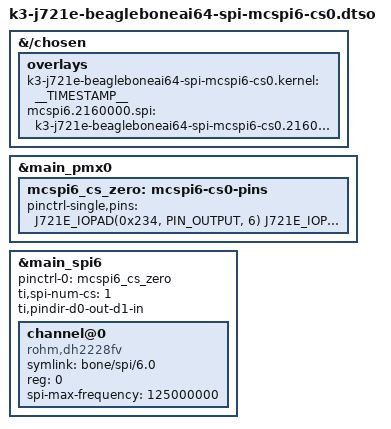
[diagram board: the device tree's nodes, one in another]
// SPDX-License-Identifier: GPL-2.0-only OR MIT
/*
 * DT Overlay for pins P9_28(cs0), P9_31(clk), P9_30(MOSI), P9_29B(MISO) SPI6 connections within the expansion header.
 *
 * Copyright (C) 2023 Texas Instruments Incorporated - https://www.ti.com/
 *
 */

/dts-v1/;
/plugin/;

#include <dt-bindings/gpio/gpio.h>
#include "ti/k3-pinctrl.h"

/*
 * Helper to show loaded overlays under: /proc/device-tree/chosen/overlays/
*/
&{/chosen} {
        overlays {
                k3-j721e-beagleboneai64-spi-mcspi6-cs0.kernel = __TIMESTAMP__;
                mcspi6.2160000.spi = "k3-j721e-beagleboneai64-spi-mcspi6-cs0.2160000";
        };
};

/* To figure out which SoC pad numbers go with which BB header pins, look at columns A and B
 * in the following spreadsheet. To figure out mux modes, look at row 10.
 * https://drive.google.com/file/d/15NLaUeMBy-iT8s6rFrP4Esf0Qh57T4xu/view?pli=1
 *
 * To figure out the addresses of SoC pads, look at table "Table 5-125. Pin Multiplexing" in the TDA4VM Processors datasheet
 * https://www.ti.com/lit/ds/symlink/tda4vm.pdf?ts=1741890214437&ref_url=https%253A%252F%252Fwww.ti.com%252Fproduct%252FTDA4VM
 *

 * ~~ Walkthrough of process to figure out muxing ~~
 *
 * From the spreadsheet we see that pad AC22 is the first pad on BB header pin P9_22. AC22 is thus known as P9_22a. The alternative
 * pad, U29, is known as P9_22b. From Looking at the TDA4VM datasheet, we see that AC22(aka P9_22a) has the address 0x00011C09C. For 
 * the J721E_IOPAD() pin-mux macro, we need the bottom 24bits of the address, so 0x09c, or 0x9c. 
 * 
 * To mux AC22(aka P9_22a) to be SPI6_CLK, as figured out from the spreadsheet, we need to set AC22 to mux-mode 4. And since
 * a SPI clock is an output signal, the pin should be put set to PIN_OUTPUT mode.
 * So `J721E_IOPAD(0x9c, PIN_OUTPUT, 4)`
 * 
 * We will also need to disable the second SoC pad that shares the same BB header pin. The SoC pad known as pin P9_22b, or 
 * pad U29. Using the same process as walked through with pad AC22, you get the following:
 * `J721E_IOPAD(0x170, PIN_DISABLE, 7)`
 *
 * So to mux SPI6_CLK on BB pin P9_22:
 * J721E_IOPAD(0x9c, PIN_OUTPUT, 4)
 * J721E_IOPAD(0x170, PIN_DISABLE, 7)
 *
*/
&main_pmx0 {
	mcspi6_cs_zero: mcspi6-cs0-pins {
		pinctrl-single,pins = <
			J721E_IOPAD(0x234, PIN_OUTPUT, 6) /* (U3) EXT_REFCLK1.SPI7_CLK P9_31a*/
			J721E_IOPAD(0xD4, PIN_DISABLE, 7) /* (AB26) disable p9_31b */
			J721E_IOPAD(0x230, PIN_OUTPUT, 6) /* (U2) ECAP0_IN_APWM_OUT.SPI7_CS0 P9_28a */
			J721E_IOPAD(0xB0, PIN_DISABLE, 7) /* (AF28) disable p9_28b */
			J721E_IOPAD(0x238, PIN_OUTPUT, 6) /* (V6) TIMER_IO0.SPI7_D0 MOSI P9_30a */
			J721E_IOPAD(0xB4, PIN_DISABLE, 7) /* (AE28) disable P9_30b */
			J721E_IOPAD(0x23c, PIN_INPUT, 6) /* (V5) TIMER_IO1.SPI7_D1 MISO P9_29a */
			J721E_IOPAD(0xD8, PIN_DISABLE, 7) /* (AB25) disable p9_29b */

            
            /* Used TI SysConfig app to generate these, had manually adjust output modes */
            J721E_IOPAD(0x9c, PIN_OUTPUT, 4) /* (AC22) PRG1_PRU1_GPO17.SPI6_CLK P9_22a */
			J721E_IOPAD(0x74, PIN_OUTPUT, 4) /* (AC21) PRG1_PRU1_GPO7.SPI6_CS0 P9_17a */
			J721E_IOPAD(0xa0, PIN_OUTPUT, 4) /* (AJ22) PRG1_PRU1_GPO18.SPI6_D0 MOSI P9_21a */
			J721E_IOPAD(0xa4, PIN_INPUT, 4) /* (AH22) PRG1_PRU1_GPO19.SPI6_D1 MISO P9_18a */

            /* Disable SoC pins that share same BB header pins */
            /* This pin conflics*/
            J721E_IOPAD(0x170, PIN_DISABLE, 7) /* (U29) disable P9_22b */
            J721E_IOPAD(0x1D0, PIN_DISABLE, 7) /* (AA3) disable P9_17b */
            J721E_IOPAD(0x16C, PIN_DISABLE, 7) /* (U28) disable P9_21b */
            J721E_IOPAD(0x1E4, PIN_DISABLE, 7) /* (Y2) disable P9_18b */
		>;
	};
};

&main_spi6 {
    #address-cells = <1>;
    #size-cells = <0>;
    pinctrl-names = "default";
    pinctrl-0 = <&mcspi6_cs_zero>;
    ti,spi-num-cs = <1>;
    ti,pindir-d0-out-d1-in;
    status = "okay";

	/* THIS IS FOR SPIDEV, to see device at /dev/bone/spi, first run `sudo modprobe spidev` */
	/* When controlling SPI from outside linux, you may want to delete this spidev stuff */
    channel@0 {
        symlink = "bone/spi/6.0";
        compatible = "rohm,dh2228fv";
        reg = <0>; /* CE0 */
        spi-max-frequency = <125000000>;
    };
};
